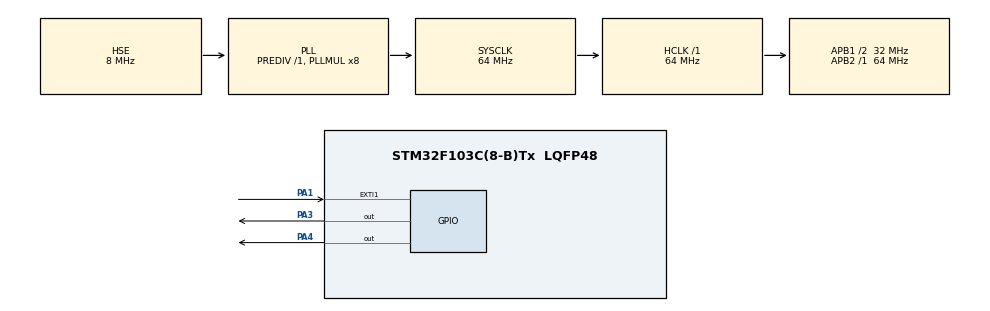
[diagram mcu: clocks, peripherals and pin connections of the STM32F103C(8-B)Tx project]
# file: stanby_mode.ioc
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Mcu.Family=STM32F1
Mcu.Name=STM32F103C(8-B)Tx
Mcu.Package=LQFP48
NVIC.EXTI1_IRQn=true\:0\:0\:false\:false\:true\:true\:true\:true
NVIC.PriorityGroup=NVIC_PRIORITYGROUP_4
NVIC.TIM1_UP_IRQn=true\:0\:0\:false\:false\:true\:true\:true\:true
PA0-WKUP.Mode=SYS_WakeUp0
PA0-WKUP.Signal=SYS_WKUP
PA1.Signal=GPXTI1
PA13.Mode=Serial_Wire
PA13.Signal=SYS_JTMS-SWDIO
PA14.Mode=Serial_Wire
PA14.Signal=SYS_JTCK-SWCLK
PA3.Signal=GPIO_Output
PA4.Signal=GPIO_Output
PD0-OSC_IN.Mode=HSE-External-Oscillator
PD0-OSC_IN.Signal=RCC_OSC_IN
PD1-OSC_OUT.Mode=HSE-External-Oscillator
PD1-OSC_OUT.Signal=RCC_OSC_OUT
ProjectManager.HeapSize=0x200
ProjectManager.StackSize=0x400
ProjectManager.TargetToolchain=STM32CubeIDE
RCC.AHBFreq_Value=64000000
RCC.APB1CLKDivider=RCC_HCLK_DIV2
RCC.APB1Freq_Value=32000000
RCC.APB1TimFreq_Value=64000000
RCC.APB2Freq_Value=64000000
RCC.APB2TimFreq_Value=64000000
RCC.HCLKFreq_Value=64000000
RCC.PLLMUL=RCC_PLL_MUL8
RCC.PLLSourceVirtual=RCC_PLLSOURCE_HSE
RCC.SYSCLKFreq_VALUE=64000000
RCC.SYSCLKSource=RCC_SYSCLKSOURCE_PLLCLK
RCC.USBFreq_Value=64000000
TIM1.Period=499
TIM1.Prescaler=63999
VP_TIM1_VS_ClockSourceINT.Mode=Internal
board=custom

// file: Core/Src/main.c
/* USER CODE BEGIN Header */
/**
  ******************************************************************************
  * @file           : main.c
  * @brief          : Main program body
  ******************************************************************************
  * @attention
  *
  * Copyright (c) 2025 STMicroelectronics.
  * All rights reserved.
  *
  * This software is licensed under terms that can be found in the LICENSE file
  * in the root directory of this software component.
  * If no LICENSE file comes with this software, it is provided AS-IS.
  *
  ******************************************************************************
  */
/* USER CODE END Header */
#include "main.h"

/* USER CODE BEGIN PD */
volatile uint8_t EnterStbFlag = 0;        // Flag: request to enter standby (shared with EXTI ISR)

uint32_t counter = 0;
/* USER CODE END PD */

TIM_HandleTypeDef htim1;

void SystemClock_Config(void);
static void MX_GPIO_Init(void);
static void MX_TIM1_Init(void);

/* USER CODE BEGIN 0 */
void blink_led(){
		counter++;
		if(counter >= 1000000)
		{
				HAL_GPIO_TogglePin(GPIOA,GPIO_PIN_4);
				counter = 0;
		}
	}
// Timer interrupt for led blink
void HAL_TIM_PeriodElapsedCallback(TIM_HandleTypeDef *htim)
{
		if(htim->Instance == htim1.Instance){
				HAL_GPIO_TogglePin(GPIOA,GPIO_PIN_3);
		}
}
/* USER CODE END 0 */

int main(void)
{

  /* MCU Configuration--------------------------------------------------------*/

  /* Reset of all peripherals, Initializes the Flash interface and the Systick. */
  HAL_Init();

  /* Configure the system clock */
  SystemClock_Config();

  /* Initialize all configured peripherals */
  MX_GPIO_Init();
  MX_TIM1_Init();
  /* USER CODE BEGIN 2 */

	HAL_TIM_Base_Start_IT(&htim1);

  /* USER CODE END 2 */

  /* Infinite loop */
  /* USER CODE BEGIN WHILE */
  while (1)
  {
			if(EnterStbFlag){

				EnterStbFlag = 0;

				__HAL_PWR_CLEAR_FLAG(PWR_FLAG_WU);

				HAL_PWR_EnableWakeUpPin(PWR_WAKEUP_PIN1); // pa0 syswkup

				HAL_PWR_EnterSTANDBYMode();
			}

			if (__HAL_PWR_GET_FLAG(PWR_FLAG_SB) == 1)
				{
					__HAL_PWR_CLEAR_FLAG(PWR_FLAG_SB);
				}

			blink_led();

    /* USER CODE END WHILE */

  }
}

void SystemClock_Config(void)
{
  RCC_OscInitTypeDef RCC_OscInitStruct = {0};
  RCC_ClkInitTypeDef RCC_ClkInitStruct = {0};

  /** Initializes the RCC Oscillators according to the specified parameters
  * in the RCC_OscInitTypeDef structure.
  */
  RCC_OscInitStruct.OscillatorType = RCC_OSCILLATORTYPE_HSE;
  RCC_OscInitStruct.HSEState = RCC_HSE_ON;
  RCC_OscInitStruct.HSEPredivValue = RCC_HSE_PREDIV_DIV1;
  RCC_OscInitStruct.HSIState = RCC_HSI_ON;
  RCC_OscInitStruct.PLL.PLLState = RCC_PLL_ON;
  RCC_OscInitStruct.PLL.PLLSource = RCC_PLLSOURCE_HSE;
  RCC_OscInitStruct.PLL.PLLMUL = RCC_PLL_MUL8;
  if (HAL_RCC_OscConfig(&RCC_OscInitStruct) != HAL_OK)
  {
    Error_Handler();
  }

  /** Initializes the CPU, AHB and APB buses clocks
  */
  RCC_ClkInitStruct.ClockType = RCC_CLOCKTYPE_HCLK|RCC_CLOCKTYPE_SYSCLK
                              |RCC_CLOCKTYPE_PCLK1|RCC_CLOCKTYPE_PCLK2;
  RCC_ClkInitStruct.SYSCLKSource = RCC_SYSCLKSOURCE_PLLCLK;
  RCC_ClkInitStruct.AHBCLKDivider = RCC_SYSCLK_DIV1;
  RCC_ClkInitStruct.APB1CLKDivider = RCC_HCLK_DIV2;
  RCC_ClkInitStruct.APB2CLKDivider = RCC_HCLK_DIV1;

  if (HAL_RCC_ClockConfig(&RCC_ClkInitStruct, FLASH_LATENCY_2) != HAL_OK)
  {
    Error_Handler();
  }
}

static void MX_TIM1_Init(void)
{

  TIM_ClockConfigTypeDef sClockSourceConfig = {0};
  TIM_MasterConfigTypeDef sMasterConfig = {0};

  htim1.Instance = TIM1;
  htim1.Init.Prescaler = 63999;
  htim1.Init.CounterMode = TIM_COUNTERMODE_UP;
  htim1.Init.Period = 499;
  htim1.Init.ClockDivision = TIM_CLOCKDIVISION_DIV1;
  htim1.Init.RepetitionCounter = 0;
  htim1.Init.AutoReloadPreload = TIM_AUTORELOAD_PRELOAD_DISABLE;
  if (HAL_TIM_Base_Init(&htim1) != HAL_OK)
  {
    Error_Handler();
  }
  sClockSourceConfig.ClockSource = TIM_CLOCKSOURCE_INTERNAL;
  if (HAL_TIM_ConfigClockSource(&htim1, &sClockSourceConfig) != HAL_OK)
  {
    Error_Handler();
  }
  sMasterConfig.MasterOutputTrigger = TIM_TRGO_RESET;
  sMasterConfig.MasterSlaveMode = TIM_MASTERSLAVEMODE_DISABLE;
  if (HAL_TIMEx_MasterConfigSynchronization(&htim1, &sMasterConfig) != HAL_OK)
  {
    Error_Handler();
  }

}

static void MX_GPIO_Init(void)
{
  GPIO_InitTypeDef GPIO_InitStruct = {0};

  /* GPIO Ports Clock Enable */
  __HAL_RCC_GPIOD_CLK_ENABLE();
  __HAL_RCC_GPIOA_CLK_ENABLE();

  /*Configure GPIO pin Output Level */
  HAL_GPIO_WritePin(GPIOA, GPIO_PIN_3|GPIO_PIN_4, GPIO_PIN_RESET);

  /*Configure GPIO pin : PA1 */
  GPIO_InitStruct.Pin = GPIO_PIN_1;
  GPIO_InitStruct.Mode = GPIO_MODE_IT_RISING;
  GPIO_InitStruct.Pull = GPIO_NOPULL;
  HAL_GPIO_Init(GPIOA, &GPIO_InitStruct);

  /*Configure GPIO pins : PA3 PA4 */
  GPIO_InitStruct.Pin = GPIO_PIN_3|GPIO_PIN_4;
  GPIO_InitStruct.Mode = GPIO_MODE_OUTPUT_PP;
  GPIO_InitStruct.Pull = GPIO_NOPULL;
  GPIO_InitStruct.Speed = GPIO_SPEED_FREQ_LOW;
  HAL_GPIO_Init(GPIOA, &GPIO_InitStruct);

  /* EXTI interrupt init*/
  HAL_NVIC_SetPriority(EXTI1_IRQn, 0, 0);
  HAL_NVIC_EnableIRQ(EXTI1_IRQn);

}

/* USER CODE BEGIN 4 */
void HAL_GPIO_EXTI_Callback(uint16_t GPIO_Pin)
{
		if(GPIO_Pin == GPIO_PIN_1) // Stop control button
		{
						EnterStbFlag = 1;
		}

}
/* USER CODE END 4 */

void Error_Handler(void)
{
  __disable_irq();
  while (1)
  {
  }
}
